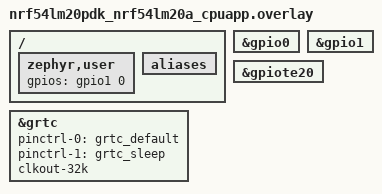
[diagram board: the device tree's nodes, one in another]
/*
 * Copyright (c) 2025 Nordic Semiconductor ASA
 *
 * SPDX-License-Identifier: LicenseRef-Nordic-5-Clause
 */

/* Required loopback between:
 * GPIO P1.0 and P0.4 (GRTC 32k; defined @board; no other option)
 */

/delete-node/ &led0;	/* at P1.0 */
/delete-node/ &button3;	/* at P0.4 */

/ {
	zephyr,user {
		gpios = <&gpio1 0 GPIO_ACTIVE_HIGH>;  /* Connect to dedicated GRTC output */
	};

	aliases {
		/delete-property/ led0;
		/delete-property/ sw3;
	};
};

&gpio0 {
	status = "okay";
};

&gpio1 {
	status = "okay";
};

&gpiote20 {
	status = "okay";
};

&grtc {
	pinctrl-0 = <&grtc_default>;
	pinctrl-1 = <&grtc_sleep>;
	pinctrl-names = "default", "sleep";
	clkout-32k;
};
